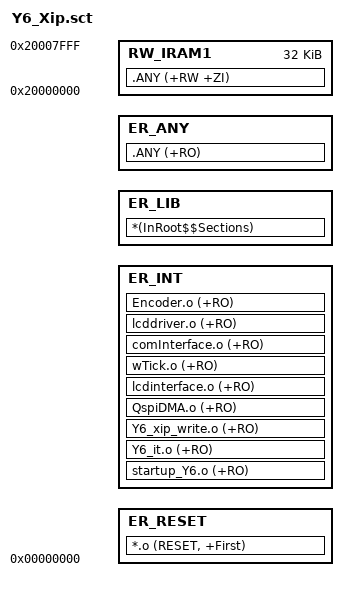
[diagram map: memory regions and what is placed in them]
; *************************************************************
; *** Scatter-Loading Description File generated by uVision ***
; *************************************************************

LR_IROM1 0x00000000 0x00080000  {    ; load region size_region
  ER_RESET 0x00000000 {  ; load address = execution address
   *.o (RESET, +First)
  }
  ER_INT +0 {
   startup_Y6.o (+RO)
   Y6_it.o  (+RO)
   Y6_xip_write.o (+RO)
   QspiDMA.o (+RO)
   lcdinterface.o (+RO)
   wTick.o (+RO)
   ;wmessage.o (+RO)
   comInterface.o (+RO)
   ;resload.o  (+RO)
   ;touchdriver.o (+RO)
   lcddriver.o (+RO)
   ;lcdWrite.o (+RO)
   ;tslib.o (+RO)
   Encoder.o (+RO)
   ;systemSPI.o (+RO)
   ;Y6_qspi.o (+RO)
   ;SystemHeart.o (+RO)
   ;systemmemory.o (+RO)
  }
  ER_LIB +0 {
   *(InRoot$$Sections)
   ;printf8.o(+RO)
  }
  ER_ANY +0 {
   .ANY (+RO)
  }
  RW_IRAM1 0x20000000 0x00008000  {  ; RW data
   .ANY (+RW +ZI)
  }
}
